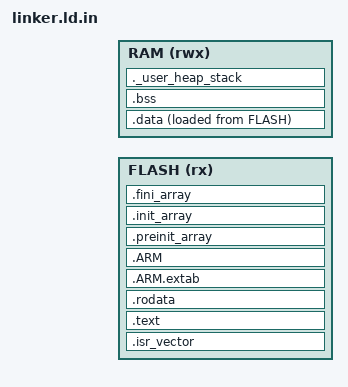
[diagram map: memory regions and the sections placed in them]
/*
 * linker.ld — minimal Cortex-M4 linker script for @BOARD_NAME@ (@MCU@)
 *
 * Memory layout:
 *   FLASH: @FLASH_ORIGIN@ .. (+@FLASH_SIZE@)
 *   RAM:   @RAM_ORIGIN@ .. (+@RAM_SIZE@)
 *
 * Generated by embed. Safe to edit; regeneration will NOT overwrite.
 */

ENTRY(Reset_Handler)

MEMORY
{
    FLASH (rx)  : ORIGIN = @FLASH_ORIGIN@, LENGTH = @FLASH_SIZE@
    RAM   (rwx) : ORIGIN = @RAM_ORIGIN@,   LENGTH = @RAM_SIZE@
}

/* Stack grows down from the top of RAM */
_stack_top = ORIGIN(RAM) + LENGTH(RAM);

/* Minimum sizes we require to link (tune as needed) */
_min_stack_size = 0x400;   /*  1 KB */
_min_heap_size  = 0x200;   /* 512 B */

SECTIONS
{
    /* ── Interrupt vector table at the start of flash ──────────────── */
    .isr_vector :
    {
        . = ALIGN(4);
        KEEP(*(.isr_vector))
        . = ALIGN(4);
    } > FLASH

    /* ── Code ──────────────────────────────────────────────────────── */
    .text :
    {
        . = ALIGN(4);
        *(.text)
        *(.text*)
        *(.glue_7)
        *(.glue_7t)
        *(.eh_frame)
        KEEP(*(.init))
        KEEP(*(.fini))
        . = ALIGN(4);
        _etext = .;
    } > FLASH

    /* ── Read-only data ────────────────────────────────────────────── */
    .rodata :
    {
        . = ALIGN(4);
        *(.rodata)
        *(.rodata*)
        . = ALIGN(4);
    } > FLASH

    .ARM.extab :
    {
        *(.ARM.extab* .gnu.linkonce.armextab.*)
    } > FLASH

    .ARM :
    {
        __exidx_start = .;
        *(.ARM.exidx*)
        __exidx_end = .;
    } > FLASH

    /* ── Preinit / Init / Fini arrays (for C++ constructors etc.) ──── */
    .preinit_array :
    {
        PROVIDE_HIDDEN(__preinit_array_start = .);
        KEEP(*(.preinit_array*))
        PROVIDE_HIDDEN(__preinit_array_end = .);
    } > FLASH

    .init_array :
    {
        PROVIDE_HIDDEN(__init_array_start = .);
        KEEP(*(SORT(.init_array.*)))
        KEEP(*(.init_array*))
        PROVIDE_HIDDEN(__init_array_end = .);
    } > FLASH

    .fini_array :
    {
        PROVIDE_HIDDEN(__fini_array_start = .);
        KEEP(*(SORT(.fini_array.*)))
        KEEP(*(.fini_array*))
        PROVIDE_HIDDEN(__fini_array_end = .);
    } > FLASH

    /* Load address of .data in flash (where initializers live) */
    _sidata = LOADADDR(.data);

    /* ── .data: initialized RAM vars (loaded from flash by startup) ── */
    .data :
    {
        . = ALIGN(4);
        _sdata = .;
        *(.data)
        *(.data*)
        . = ALIGN(4);
        _edata = .;
    } > RAM AT > FLASH

    /* ── .bss: zero-initialized vars ───────────────────────────────── */
    .bss :
    {
        . = ALIGN(4);
        _sbss = .;
        __bss_start__ = .;
        *(.bss)
        *(.bss*)
        *(COMMON)
        . = ALIGN(4);
        _ebss = .;
        __bss_end__ = .;
    } > RAM

    /* ── Heap + stack guard ────────────────────────────────────────── */
    ._user_heap_stack :
    {
        . = ALIGN(8);
        PROVIDE(end = .);
        PROVIDE(_end = .);
        . = . + _min_heap_size;
        . = . + _min_stack_size;
        . = ALIGN(8);
    } > RAM

    .ARM.attributes 0 : { *(.ARM.attributes) }
}
